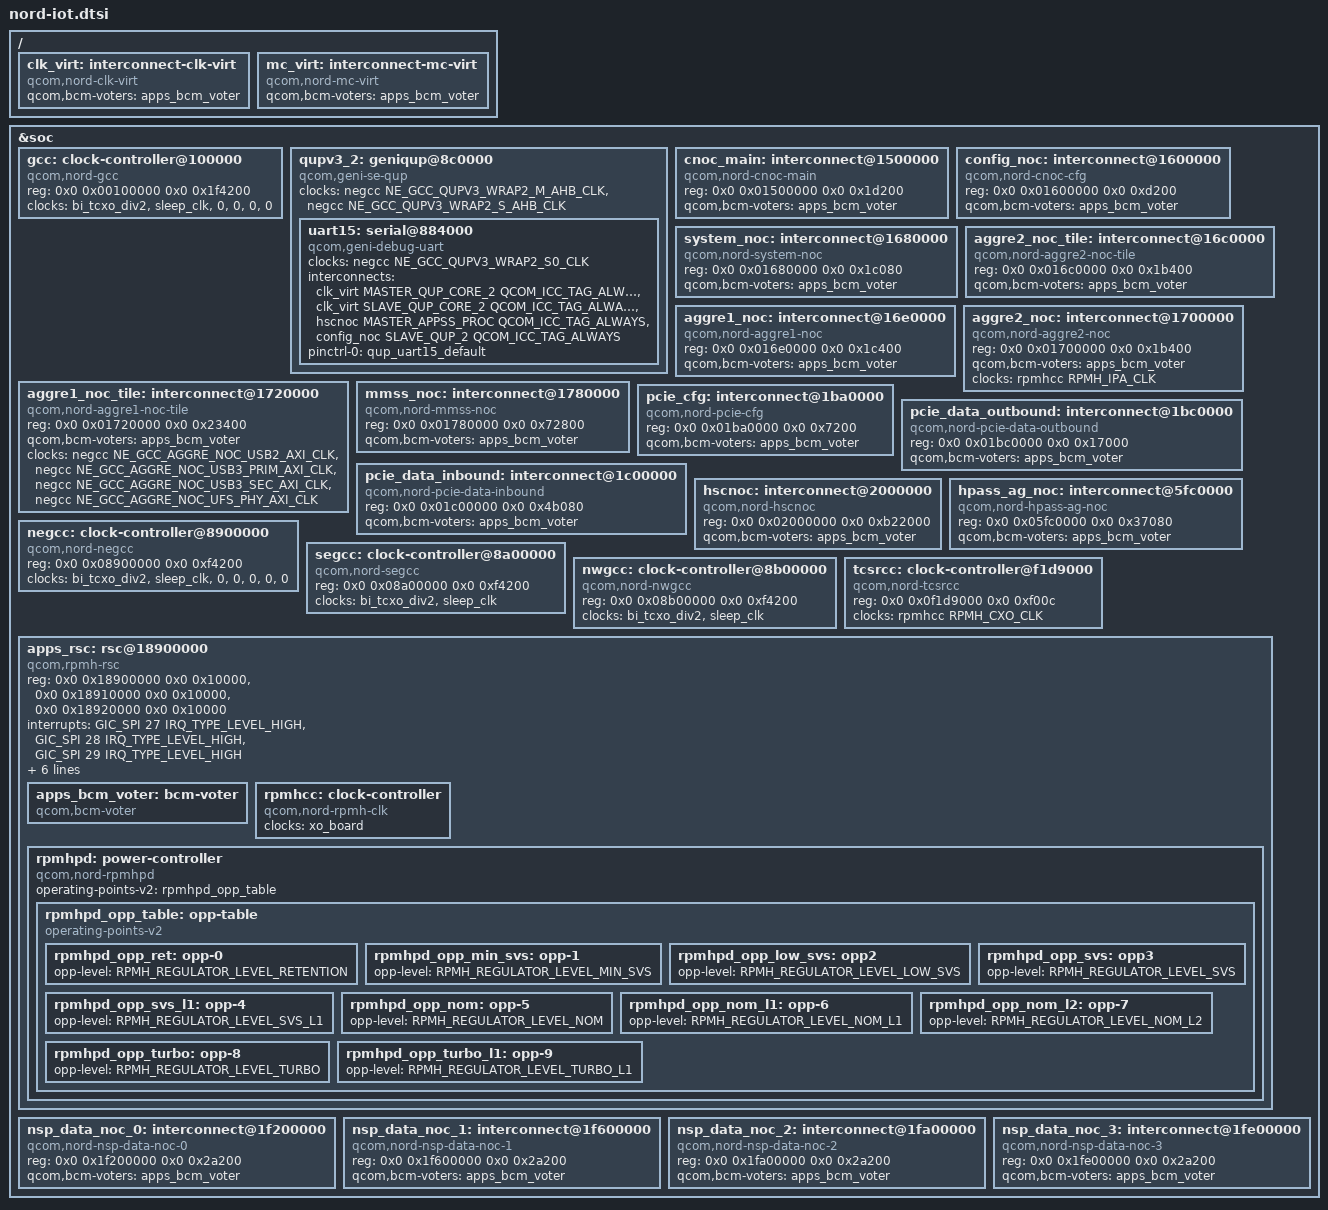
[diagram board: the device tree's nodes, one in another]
// SPDX-License-Identifier: BSD-3-Clause
/*
 * Copyright (c) Qualcomm Technologies, Inc. and/or its subsidiaries.
 */

#include <dt-bindings/clock/qcom,nord-gcc.h>
#include <dt-bindings/clock/qcom,nord-negcc.h>
#include <dt-bindings/clock/qcom,nord-nwgcc.h>
#include <dt-bindings/clock/qcom,nord-segcc.h>
#include <dt-bindings/clock/qcom,rpmh.h>
#include <dt-bindings/interconnect/qcom,icc.h>
#include <dt-bindings/interconnect/qcom,nord-rpmh.h>
#include <dt-bindings/power/qcom-rpmpd.h>
#include <dt-bindings/soc/qcom,rpmh-rsc.h>

#include "nord.dtsi"

/ {
	clk_virt: interconnect-clk-virt {
		compatible = "qcom,nord-clk-virt";
		#interconnect-cells = <2>;
		qcom,bcm-voters = <&apps_bcm_voter>;
	};

	mc_virt: interconnect-mc-virt {
		compatible = "qcom,nord-mc-virt";
		#interconnect-cells = <2>;
		qcom,bcm-voters = <&apps_bcm_voter>;
	};
};

&soc {
	gcc: clock-controller@100000 {
		compatible = "qcom,nord-gcc";
		reg = <0x0 0x00100000 0x0 0x1f4200>;
		clocks = <&bi_tcxo_div2>,
			 <&sleep_clk>,
			 <0>,
			 <0>,
			 <0>,
			 <0>;
		#clock-cells = <1>;
		#reset-cells = <1>;
		#power-domain-cells = <1>;
	};

	qupv3_2: geniqup@8c0000 {
		compatible = "qcom,geni-se-qup";
		clocks = <&negcc NE_GCC_QUPV3_WRAP2_M_AHB_CLK>,
			 <&negcc NE_GCC_QUPV3_WRAP2_S_AHB_CLK>;
		clock-names = "m-ahb",
			      "s-ahb";

		uart15: serial@884000 {
			compatible = "qcom,geni-debug-uart";
			clocks = <&negcc NE_GCC_QUPV3_WRAP2_S0_CLK>;
			clock-names = "se";
			interconnects = <&clk_virt MASTER_QUP_CORE_2 QCOM_ICC_TAG_ALWAYS
					 &clk_virt SLAVE_QUP_CORE_2 QCOM_ICC_TAG_ALWAYS>,
					<&hscnoc MASTER_APPSS_PROC QCOM_ICC_TAG_ALWAYS
					 &config_noc SLAVE_QUP_2 QCOM_ICC_TAG_ALWAYS>;
			interconnect-names = "qup-core", "qup-config";
			pinctrl-0 = <&qup_uart15_default>;
			pinctrl-names = "default";
		};
	};

	cnoc_main: interconnect@1500000 {
		compatible = "qcom,nord-cnoc-main";
		reg = <0x0 0x01500000 0x0 0x1d200>;
		#interconnect-cells = <2>;
		qcom,bcm-voters = <&apps_bcm_voter>;
	};

	config_noc: interconnect@1600000 {
		compatible = "qcom,nord-cnoc-cfg";
		reg = <0x0 0x01600000 0x0 0xd200>;
		#interconnect-cells = <2>;
		qcom,bcm-voters = <&apps_bcm_voter>;
	};

	system_noc: interconnect@1680000 {
		compatible = "qcom,nord-system-noc";
		reg = <0x0 0x01680000 0x0 0x1c080>;
		#interconnect-cells = <2>;
		qcom,bcm-voters = <&apps_bcm_voter>;
	};

	aggre2_noc_tile: interconnect@16c0000 {
		compatible = "qcom,nord-aggre2-noc-tile";
		reg = <0x0 0x016c0000 0x0 0x1b400>;
		#interconnect-cells = <2>;
		qcom,bcm-voters = <&apps_bcm_voter>;
	};

	aggre1_noc: interconnect@16e0000 {
		compatible = "qcom,nord-aggre1-noc";
		reg = <0x0 0x016e0000 0x0 0x1c400>;
		#interconnect-cells = <2>;
		qcom,bcm-voters = <&apps_bcm_voter>;
	};

	aggre2_noc: interconnect@1700000 {
		compatible = "qcom,nord-aggre2-noc";
		reg = <0x0 0x01700000 0x0 0x1b400>;
		#interconnect-cells = <2>;
		qcom,bcm-voters = <&apps_bcm_voter>;
		clocks = <&rpmhcc RPMH_IPA_CLK>;
	};

	aggre1_noc_tile: interconnect@1720000 {
		compatible = "qcom,nord-aggre1-noc-tile";
		reg = <0x0 0x01720000 0x0 0x23400>;
		#interconnect-cells = <2>;
		qcom,bcm-voters = <&apps_bcm_voter>;
		clocks = <&negcc NE_GCC_AGGRE_NOC_USB2_AXI_CLK>,
			 <&negcc NE_GCC_AGGRE_NOC_USB3_PRIM_AXI_CLK>,
			 <&negcc NE_GCC_AGGRE_NOC_USB3_SEC_AXI_CLK>,
			 <&negcc NE_GCC_AGGRE_NOC_UFS_PHY_AXI_CLK>;
	};

	mmss_noc: interconnect@1780000 {
		compatible = "qcom,nord-mmss-noc";
		reg = <0x0 0x01780000 0x0 0x72800>;
		#interconnect-cells = <2>;
		qcom,bcm-voters = <&apps_bcm_voter>;
	};

	pcie_cfg: interconnect@1ba0000 {
		compatible = "qcom,nord-pcie-cfg";
		reg = <0x0 0x01ba0000 0x0 0x7200>;
		#interconnect-cells = <2>;
		qcom,bcm-voters = <&apps_bcm_voter>;
	};

	pcie_data_outbound: interconnect@1bc0000 {
		compatible = "qcom,nord-pcie-data-outbound";
		reg = <0x0 0x01bc0000 0x0 0x17000>;
		#interconnect-cells = <2>;
		qcom,bcm-voters = <&apps_bcm_voter>;
	};

	pcie_data_inbound: interconnect@1c00000 {
		compatible = "qcom,nord-pcie-data-inbound";
		reg = <0x0 0x01c00000 0x0 0x4b080>;
		#interconnect-cells = <2>;
		qcom,bcm-voters = <&apps_bcm_voter>;
	};

	hscnoc: interconnect@2000000 {
		compatible = "qcom,nord-hscnoc";
		reg = <0x0 0x02000000 0x0 0xb22000>;
		#interconnect-cells = <2>;
		qcom,bcm-voters = <&apps_bcm_voter>;
	};

	hpass_ag_noc: interconnect@5fc0000 {
		compatible = "qcom,nord-hpass-ag-noc";
		reg = <0x0  0x05fc0000 0x0 0x37080>;
		#interconnect-cells = <2>;
		qcom,bcm-voters = <&apps_bcm_voter>;
	};

	negcc: clock-controller@8900000 {
		compatible = "qcom,nord-negcc";
		reg = <0x0 0x08900000 0x0 0xf4200>;
		clocks = <&bi_tcxo_div2>,
			 <&sleep_clk>,
			 <0>,
			 <0>,
			 <0>,
			 <0>,
			 <0>;
		#clock-cells = <1>;
		#reset-cells = <1>;
		#power-domain-cells = <1>;
	};

	segcc: clock-controller@8a00000 {
		compatible = "qcom,nord-segcc";
		reg = <0x0 0x08a00000 0x0 0xf4200>;
		clocks = <&bi_tcxo_div2>,
			 <&sleep_clk>;
		#clock-cells = <1>;
		#reset-cells = <1>;
		#power-domain-cells = <1>;
	};

	nwgcc: clock-controller@8b00000 {
		compatible = "qcom,nord-nwgcc";
		reg = <0x0 0x08b00000 0x0 0xf4200>;
		clocks = <&bi_tcxo_div2>,
			 <&sleep_clk>;
		#clock-cells = <1>;
		#reset-cells = <1>;
		#power-domain-cells = <1>;
	};

	tcsrcc: clock-controller@f1d9000 {
		compatible = "qcom,nord-tcsrcc", "syscon";
		reg = <0x0 0x0f1d9000 0x0 0xf00c>;
		clocks = <&rpmhcc RPMH_CXO_CLK>;
		#clock-cells = <1>;
		#reset-cells = <1>;
	};

	apps_rsc: rsc@18900000 {
		compatible = "qcom,rpmh-rsc";
		reg = <0x0 0x18900000 0x0 0x10000>,
		      <0x0 0x18910000 0x0 0x10000>,
		      <0x0 0x18920000 0x0 0x10000>;
		reg-names = "drv-0",
			    "drv-1",
			    "drv-2";
		interrupts = <GIC_SPI 27 IRQ_TYPE_LEVEL_HIGH>,
			     <GIC_SPI 28 IRQ_TYPE_LEVEL_HIGH>,
			     <GIC_SPI 29 IRQ_TYPE_LEVEL_HIGH>;
		qcom,tcs-offset = <0xd00>;
		qcom,drv-id = <2>;
		qcom,tcs-config = <ACTIVE_TCS 3>,
				  <SLEEP_TCS 2>,
				  <WAKE_TCS 2>,
				  <CONTROL_TCS 0>;
		label = "apps_rsc";
		power-domains = <&system_pd>;

		apps_bcm_voter: bcm-voter {
			compatible = "qcom,bcm-voter";
		};

		rpmhcc: clock-controller {
			compatible = "qcom,nord-rpmh-clk";
			clocks = <&xo_board>;
			clock-names = "xo";
			#clock-cells = <1>;
		};

		rpmhpd: power-controller {
			compatible = "qcom,nord-rpmhpd";
			#power-domain-cells = <1>;
			operating-points-v2 = <&rpmhpd_opp_table>;

			rpmhpd_opp_table: opp-table {
				compatible = "operating-points-v2";

				rpmhpd_opp_ret: opp-0 {
					opp-level = <RPMH_REGULATOR_LEVEL_RETENTION>;
				};

				rpmhpd_opp_min_svs: opp-1 {
					opp-level = <RPMH_REGULATOR_LEVEL_MIN_SVS>;
				};

				rpmhpd_opp_low_svs: opp2 {
					opp-level = <RPMH_REGULATOR_LEVEL_LOW_SVS>;
				};

				rpmhpd_opp_svs: opp3 {
					opp-level = <RPMH_REGULATOR_LEVEL_SVS>;
				};

				rpmhpd_opp_svs_l1: opp-4 {
					opp-level = <RPMH_REGULATOR_LEVEL_SVS_L1>;
				};

				rpmhpd_opp_nom: opp-5 {
					opp-level = <RPMH_REGULATOR_LEVEL_NOM>;
				};

				rpmhpd_opp_nom_l1: opp-6 {
					opp-level = <RPMH_REGULATOR_LEVEL_NOM_L1>;
				};

				rpmhpd_opp_nom_l2: opp-7 {
					opp-level = <RPMH_REGULATOR_LEVEL_NOM_L2>;
				};

				rpmhpd_opp_turbo: opp-8 {
					opp-level = <RPMH_REGULATOR_LEVEL_TURBO>;
				};

				rpmhpd_opp_turbo_l1: opp-9 {
					opp-level = <RPMH_REGULATOR_LEVEL_TURBO_L1>;
				};
			};
		};
	};

	nsp_data_noc_0: interconnect@1f200000 {
		compatible = "qcom,nord-nsp-data-noc-0";
		reg = <0x0 0x1f200000 0x0 0x2a200>;
		#interconnect-cells = <2>;
		qcom,bcm-voters = <&apps_bcm_voter>;
	};

	nsp_data_noc_1: interconnect@1f600000 {
		compatible = "qcom,nord-nsp-data-noc-1";
		reg = <0x0 0x1f600000 0x0 0x2a200>;
		#interconnect-cells = <2>;
		qcom,bcm-voters = <&apps_bcm_voter>;
	};

	nsp_data_noc_2: interconnect@1fa00000 {
		compatible = "qcom,nord-nsp-data-noc-2";
		reg = <0x0 0x1fa00000 0x0 0x2a200>;
		#interconnect-cells = <2>;
		qcom,bcm-voters = <&apps_bcm_voter>;
	};

	nsp_data_noc_3: interconnect@1fe00000 {
		compatible = "qcom,nord-nsp-data-noc-3";
		reg = <0x0 0x1fe00000 0x0 0x2a200>;
		#interconnect-cells = <2>;
		qcom,bcm-voters = <&apps_bcm_voter>;
	};
};
